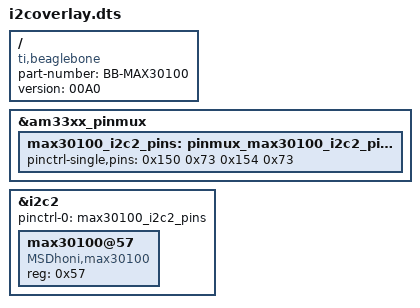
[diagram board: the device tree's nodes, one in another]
/dts-v1/;
/plugin/;

/ {
    compatible = "ti,beaglebone", "ti,beaglebone-black";

    part-number = "BB-MAX30100";
    version = "00A0";

    fragment@0 {
        target = <&am33xx_pinmux>;
        __overlay__ {
            max30100_i2c2_pins: pinmux_max30100_i2c2_pins {
                pinctrl-single,pins = <
                    0x150 0x73   /* I2C2_SCL -> P9_19 */
                    0x154 0x73   /* I2C2_SDA -> P9_20 */
                >;
            };
        };
    };

    fragment@1 {
        target = <&i2c2>;
        __overlay__ {
	    #address-cells = <1>;
            #size-cells = <0>;
            status = "okay";
            pinctrl-names = "default";
            pinctrl-0 = <&max30100_i2c2_pins>;

            max30100@57 {
                compatible = "MSDhoni,max30100";
                reg = <0x57>;
                status = "okay";
            };
        };
    };
};

